# CEC1702 register map
Vendor: Microchip Technology; Series: CEC1702Q; File version: 0
CPU: CM4 r1p0, little endian, MPU, FPU, 3 interrupt priority bits, 155 interrupts
Registers are 32-bit, read-write, reset 0x0 unless marked. A register's access mark holds for its fields unless they carry their own. Offsets are from the block's base; [hi:lo] are bit positions.

## PWM0 — This block generates a PWM output that can be used to control 4-wire fans, blinking LEDs, and other similar devices. Each PWM can generate an arbitrary duty cycle output at frequencies from less than 0.1 Hz to 24 MHz. The PWM controller can also used to generate the PROCHOT output and Speaker output.
Base 0x40005800; register names take the prefix PWM_
Same registers: PWM1 0x40005810, PWM2 0x40005820, PWM3 0x40005830, PWM4 0x40005840, PWM5 0x40005850, PWM10 0x400058A0
0x00 CNT_ON — This field determines both the frequency and duty cycle of the PWM signal. Setting this field to a value of n will cause the On time of the PWM to be n+1 cycles of the PWM Clock Source. When this field is set to zero and the PWMX_COUNTER_OFF_TIME is not set to zero, the PWM_OUTPUT is held low (Full Off).
0x04 CNT_OFF — This field determine both the frequency and duty cycle of the PWM signal. Setting this field to a value of n will cause the Off time of the PWM to be n+1 cycles of the PWM Clock Source. When this field is set to zero, the PWM_OUTPUT is held high (Full On).
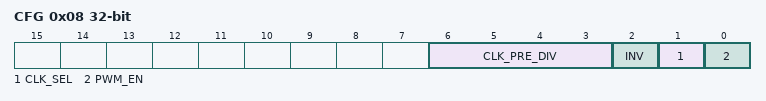
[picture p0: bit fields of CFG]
0x08 CFG — PWMx CFGURATION REGISTER
  [6:3] CLK_PRE_DIV — The Clock source for the 16-bit down counter (see PWMx Counter ON Time Register and PWMx Counter OFF Time Register) is determined by bit D1 of this register. The Clock source is then divided by the value of Pre-Divider+1 and the resulting signal determines the rate at which the down counter will be decremented. For example, a Pre-Divider value of 1 divides the input clock by 2 and a value of 2 divides the input clock by 3. A Pre-Divider of 0 will disable the Pre-Divider option.
  [2] INV — 1= PWM_OUTPUT ON State is active low; 0=PWM_OUTPUT ON State is active high.
  [1] CLK_SEL — This bit determines the clock source used by the PWM duty cycle and frequency control logic. 1=CLOCK_LOW. 0=CLOCK_HIGH
  [0] PWM_EN — When the PWM_EN is set to 0 the internal counters are reset and the internal state machine is set to the OFF state. In addition, the PWM_OUTPUT signal is set to the inactive state as determined by the Invert bit. The PWMx Counter ON Time Register and PWMx Counter OFF Time Register are not affected by the PWM_ENABLE bit and may be read and written while the PWM enable bit is 0. 1=Enabled (default); 0=Disabled (gates clocks to save power).

## RC_ID0 — This interface provides a single pin interface which can discriminate a number of quantized RC constants.
Base 0x40001400; register names take the prefix RC_ID_
Same registers: RC_ID1 0x40001480
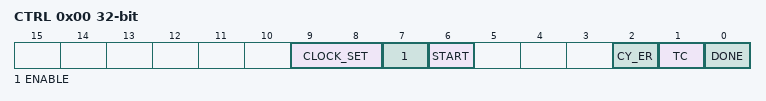
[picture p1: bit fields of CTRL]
0x00 CTRL — RC_ID Control Register
  [9:8] CLOCK_SET — This field selects the frequency of the Counter circuit clock. This field must retain the same value as long as the ENABLE bit in this register is 1.
  [7] ENABLE — Clearing the bit to 0 causes the RC_ID interface to enter the Reset state, gating its clocks, clearing the status bits in this register and entering into its lowest power state. Setting this bit to 1 causes the RC_ID interface to enter the Armed phase of an RC_ID measurement.
  [6] START — Setting this bit to 1 initiates the Discharged phase of an RC_ID measurement.
  [2] CY_ER — This bit is 1 if an RC_ID measurement encountered an error and the reading in the RC_ID Data Register is invalid. This bit is cleared to 0 when the RC_ID interface is in the Reset phase.
  [1] TC — This bit is cleared to 0 when the RC_ID interface is in the Reset phase, and set to 1 when the interface completes the Discharged phase of an RC_ID measurement.
  [0] DONE — This bit is cleared to 0 when the RC_ID interface is in the Reset phase, and set to 1 when the interface completes an RC_ID measurement.
0x04 DAT — Reads of this register provide the result of an RC_ID measurement.
  [15:0] RCID_DATA
